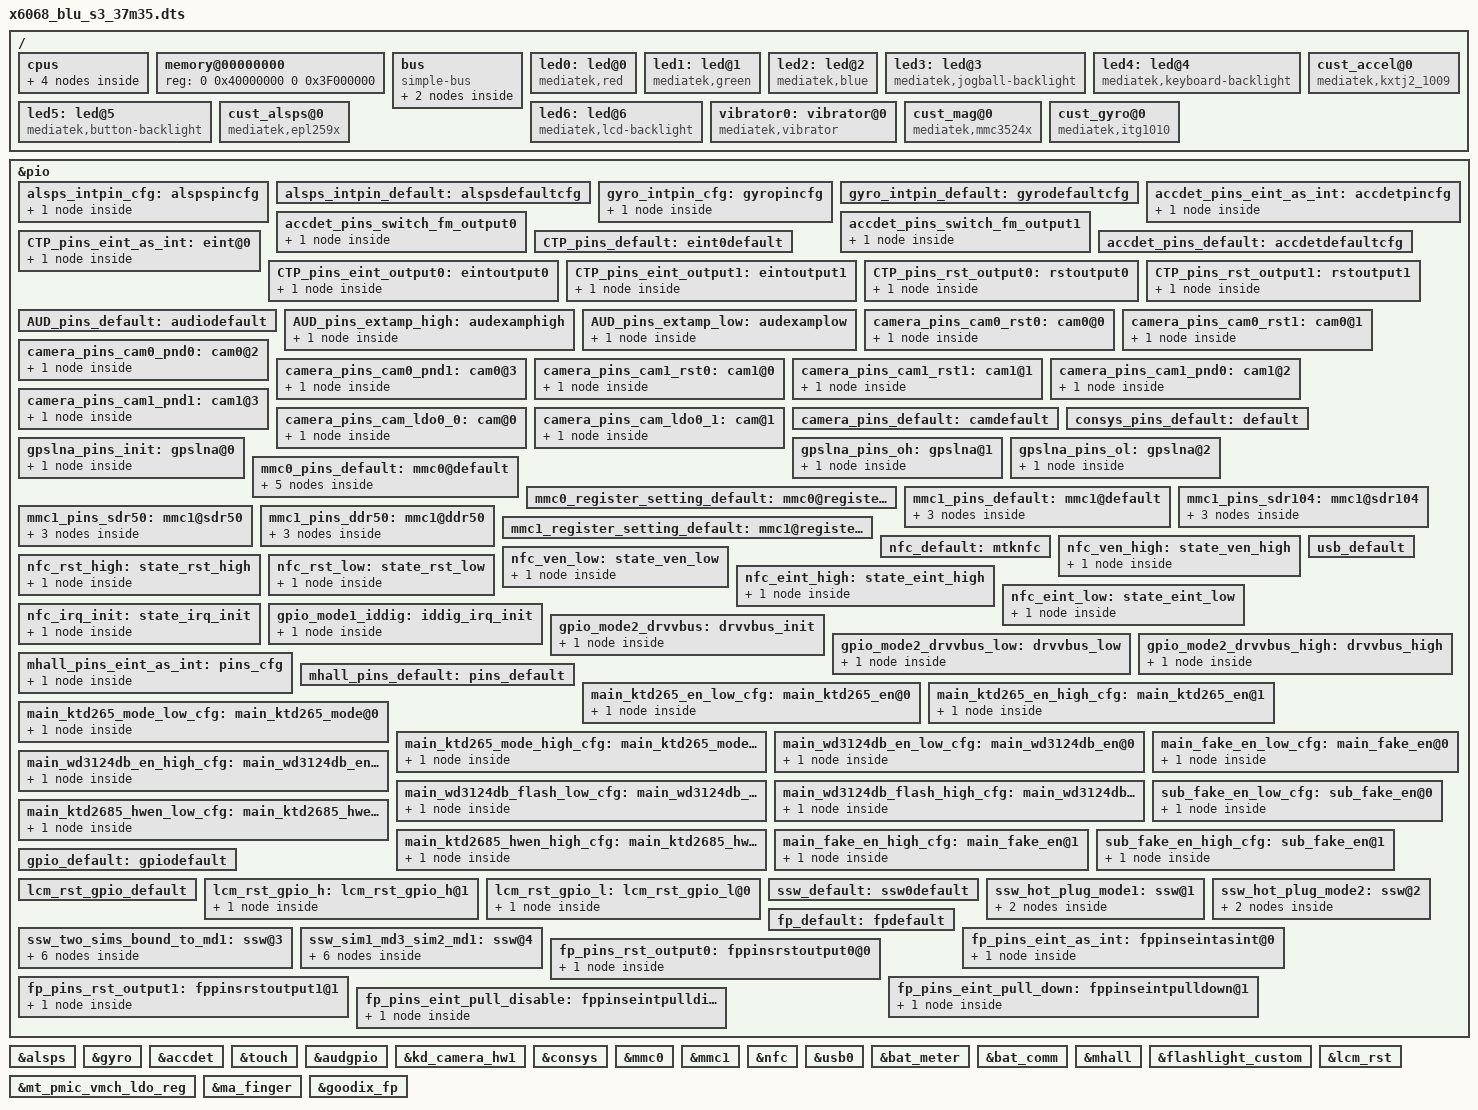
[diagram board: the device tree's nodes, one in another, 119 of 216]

/dts-v1/;

#include "mt6735m.dtsi"

/ {
	cpus {
		#address-cells = <1>;
		#size-cells = <0>;
/*		enable-method = "mediatek,mt6735-smp"; */

		cpu0: cpu@000 {
			device_type = "cpu";
			compatible = "arm,cortex-a53";
			reg = <0x000>;
			enable-method = "spin-table";
			cpu-release-addr = <0x0 0x40000200>;
			clock-frequency = <1100000000>;
		};

		cpu1: cpu@001 {
			device_type = "cpu";
			compatible = "arm,cortex-a53";
			reg = <0x001>;
			enable-method = "spin-table";
			cpu-release-addr = <0x0 0x40000200>;
			clock-frequency = <1100000000>;
		};

		cpu2: cpu@002 {
			device_type = "cpu";
			compatible = "arm,cortex-a53";
			reg = <0x002>;
			enable-method = "spin-table";
			cpu-release-addr = <0x0 0x40000200>;
			clock-frequency = <1100000000>;
		};

		cpu3: cpu@003 {
			device_type = "cpu";
			compatible = "arm,cortex-a53";
			reg = <0x003>;
			enable-method = "spin-table";
			cpu-release-addr = <0x0 0x40000200>;
			clock-frequency = <1100000000>;
		};
	};

	memory@00000000 {
		device_type = "memory";
		reg = <0 0x40000000 0 0x3F000000>;
	};

	bus {
		compatible = "simple-bus";
		#address-cells = <1>;
		#size-cells = <1>;
		ranges = <0 0 0 0xffffffff>;

		MALI@0x13040000 {
			compatible = "arm,malit720", "arm,mali-t72x", "arm,malit7xx", "arm,mali-midgard";
			reg = <0x13040000 0x4000>;
			interrupts = <0 212 0x8>, <0 211 0x8>, <0 210 0x8>;
			interrupt-names = "JOB", "MMU", "GPU";
			clock-frequency = <550000000>;
		};

		MTKFB@5e200000 {
			compatible = "mediatek,MTKFB";
			reg = <0x7F000000 0x1000000>;
		};

	};
	led0:led@0 {
		compatible = "mediatek,red";
		led_mode = <3>;
		data = <1>;
		pwm_config = <0 0 0 0 0>;
	};
	led1:led@1 {
		compatible = "mediatek,green";
		led_mode = <3>;
		data = <1>;
		pwm_config = <0 0 0 0 0>;
	};
	led2:led@2 {
		compatible = "mediatek,blue";
		led_mode = <3>;
		data = <1>;
		pwm_config = <0 0 0 0 0>;
	};
	led3:led@3 {
		compatible = "mediatek,jogball-backlight";
		led_mode = <0>;
		data = <1>;
		pwm_config = <0 0 0 0 0>;
	};
	led4:led@4 {
		compatible = "mediatek,keyboard-backlight";
		led_mode = <0>;
		data = <1>;
		pwm_config = <0 0 0 0 0>;
	};
	led5:led@5 {
		compatible = "mediatek,button-backlight";
		led_mode = <0>;
		data = <1>;
		pwm_config = <0 0 0 0 0>;
	};
	led6:led@6 {
		compatible = "mediatek,lcd-backlight";
		led_mode = <5>;
		data = <1>;
		pwm_config = <0 0 0 0 0>;
	};
	vibrator0:vibrator@0 {
		compatible = "mediatek,vibrator";
		vib_timer = <25>;
		vib_limit = <9>;
		vib_vol= <5>;
	};
 /* sensor standardization */
		cust_accel@0 {
		compatible = "mediatek,kxtj2_1009";
		i2c_num	= <2>;
		i2c_addr = <0x0E 0 0 0>;
		direction = <7>;
		power_id = <0xffff>;
		power_vol = <0>;
		firlen = <0>;
		is_batch_supported = <0>;
		};

		cust_alsps@0 {
		compatible = "mediatek,epl259x";
		i2c_num	= <2>;
		i2c_addr = <0x49 0 0 0>;
		polling_mode_ps = <0>;
		polling_mode_als = <1>;
		power_id = <0xffff>;
		power_vol = <0>;
		als_level = <20  45  70  90  150  300  500  700  1400  3600  5500  8000  15000  30000  50000>;
		als_value = <10  30  60  80  100  200  400  600  800  1000  3650  6000  10000  20000  40000  60000>;
		ps_threshold_high		=  <34>;
		ps_threshold_low		=  <28>;
		is_batch_supported_ps	= <0>;
		is_batch_supported_als	= <0>;
		ps_integration_time     =<24 >;/*epl259x use*/
		};

		cust_mag@0 {
		compatible				= "mediatek,mmc3524x";
		i2c_num					= <2>;
		i2c_addr				= <0x30 0 0 0>;
		direction				= <0>;
		power_id				= <0xffff>;
		power_vol				= <0>;
		is_batch_supported	= <0>;
		};

		cust_gyro@0 {
		compatible				= "mediatek,itg1010";
		i2c_num				= <2>;
		i2c_addr				= <0x68 0 0 0>;
		direction				= <3>;
		power_id				= <0xffff>;
		power_vol				= <0>;
		firlen					= <0>;
		is_batch_supported	= <0>;
		};
};
/* sensor gpio standization */
&pio {
	alsps_intpin_cfg: alspspincfg {

	    pins_cmd_dat {
			pins = <PINMUX_GPIO80__FUNC_GPIO80>;
			slew-rate = <0>;
			bias-pull-up = <00>;
		};
	};

	alsps_intpin_default: alspsdefaultcfg {

	};

	gyro_intpin_cfg: gyropincfg {

		pins_cmd_dat {
			pins = <PINMUX_GPIO67__FUNC_GPIO67>;
			slew-rate = <0>;
			bias-pull-down = <00>;
		};
	};

	gyro_intpin_default: gyrodefaultcfg {

	};
};
&alsps {
	pinctrl-names = "pin_default", "pin_cfg";
	pinctrl-0 = <&alsps_intpin_default>;
	pinctrl-1 = <&alsps_intpin_cfg>;
	status = "okay";

};

&gyro {
	pinctrl-names = "pin_default", "pin_cfg";
	pinctrl-0 = <&gyro_intpin_default>;
	pinctrl-1 = <&gyro_intpin_cfg>;
	status = "okay";

};
/* sensor end */

/* ACCDET start */
&pio {
	accdet_pins_eint_as_int: accdetpincfg {
	
		pins_cmd_dat {
		pins = <PINMUX_GPIO6__FUNC_GPIO6>;
		slew-rate = <0>;
		bias-disable;
		};
	};
	
	accdet_pins_switch_fm_output0: accdet_pins_switch_fm_output0 {
		pins_cmd_dat {
			pins = <PINMUX_GPIO11__FUNC_GPIO11>;
			slew-rate = <1>;
			output-low;
		};
	};
	accdet_pins_switch_fm_output1: accdet_pins_switch_fm_output1 {
		pins_cmd_dat {
			pins = <PINMUX_GPIO11__FUNC_GPIO11>;
			slew-rate = <1>;
			output-high;
		};
	};
	
	accdet_pins_default: accdetdefaultcfg {
	
	};
};
&accdet {
	accdet-mic-vol = <7>;
	switch_fm_support = <1>;  /* support*/
	headset-mode-setting = <0x500 0x200 1 0x1F0 0x800 0x800 0x20>;
	accdet-plugout-debounce = <20>;
	/*1:ACC mode, 2:low cost without in bias, 6:low cost with in bias*/
	accdet-mic-mode = <1>;
	/*0--MD_MAX--UP_MAX--DW_MAX*/
	headset-three-key-threshold = <0 80 220 500>;
	/*0--MD_MAX--VOICE_MAX--UP_MAX--DW_MAX*/
	headset-four-key-threshold = <0 58 121 192 450>;
	/* accdet+eint mode start */
	debounce = <6 256000>;
	interrupts = <6 IRQ_TYPE_LEVEL_LOW>;
	pinctrl-names = "default", "state_eint_as_int", 
						"state_switch_fm_output0", "state_switch_fm_output1";
	pinctrl-0 = <&accdet_pins_default>;
	pinctrl-1 = <&accdet_pins_eint_as_int>;
	pinctrl-2 = <&accdet_pins_switch_fm_output0>;
	pinctrl-3 = <&accdet_pins_switch_fm_output1>;
	status = "okay";
	/* accdet+eint mode end */
};
/* ACCDET end */

&touch {
	tpd-resolution = <720 1280>;
	use-tpd-button = <1>;
	tpd-key-num = <3>;
	tpd-key-local= <139 172 158 0>;
	tpd-key-dim-local = <60 1500 100 40 180 1500 100 40 300 1500 100 40 0 0 0 0>;
	tpd-max-touch-num = <5>;
	tpd-filter-enable = <0>;
	tpd-filter-pixel-density = <93>;
	tpd-filter-custom-prameters = <0 0 0 0 0 0 0 0 0 0 0 0>;
	tpd-filter-custom-speed = <0 0 0>;
	pinctrl-names = "default", "state_eint_as_int", "state_eint_output0", "state_eint_output1",
		"state_rst_output0", "state_rst_output1";
	pinctrl-0 = <&CTP_pins_default>;
	pinctrl-1 = <&CTP_pins_eint_as_int>;
	pinctrl-2 = <&CTP_pins_eint_output0>;
	pinctrl-3 = <&CTP_pins_eint_output1>;
	pinctrl-4 = <&CTP_pins_rst_output0>;
	pinctrl-5 = <&CTP_pins_rst_output1>;
	status = "okay";
};
&pio {
	CTP_pins_default: eint0default {
	};
	CTP_pins_eint_as_int: eint@0 {
		pins_cmd_dat {
			pins = <PINMUX_GPIO10__FUNC_GPIO10>;
			slew-rate = <0>;
			bias-disable;
		};
	};
	CTP_pins_eint_output0: eintoutput0 {
		pins_cmd_dat {
			pins = <PINMUX_GPIO10__FUNC_GPIO10>;
			slew-rate = <1>;
			output-low;
		};
	};
	CTP_pins_eint_output1: eintoutput1 {
		pins_cmd_dat {
			pins = <PINMUX_GPIO10__FUNC_GPIO10>;
			slew-rate = <1>;
			output-high;
		};
	};
	CTP_pins_rst_output0: rstoutput0 {
		pins_cmd_dat {
			pins = <PINMUX_GPIO62__FUNC_GPIO62>;
			slew-rate = <1>;
			output-low;
		};
	};
	CTP_pins_rst_output1: rstoutput1 {
		pins_cmd_dat {
			pins = <PINMUX_GPIO62__FUNC_GPIO62>;
			slew-rate = <1>;
			output-high;
		};
	};
};
/* TOUCH end */

&audgpio {
	aud_pa_mode_select = <1>; /*mode0~3 (1.2W,1W,0.8W,0.6W)*/
	pinctrl-names = "default", "extamp-pullhigh", "extamp-pulllow";
	pinctrl-0 = <&AUD_pins_default>;
	pinctrl-1 = <&AUD_pins_extamp_high>;
	pinctrl-2 = <&AUD_pins_extamp_low>;
	status = "okay";
};
&pio {
	AUD_pins_default: audiodefault {
	};
	AUD_pins_extamp_high: audexamphigh {
		pins_cmd_dat {
			pins = <PINMUX_GPIO61__FUNC_GPIO61>;
				slew-rate = <1>;
				output-high;
		};
	};
	AUD_pins_extamp_low: audexamplow {
		pins_cmd_dat {
			pins = <PINMUX_GPIO61__FUNC_GPIO61>;
				slew-rate = <1>;
				output-low;
		};
	};
};
/* AUDIO end */
/* CAMERA GPIO standardization */
&pio {
	camera_pins_cam0_rst0: cam0@0 {
		pins_cmd_dat {
			pins = <PINMUX_GPIO44__FUNC_GPIO44>;/*GPIO_CAMERA_CMRST_PIN*/
			slew-rate = <1>; /*direction 0:in, 1:out*/
			output-low;/*direction out used only. output_low or high*/
		};
	};
	camera_pins_cam0_rst1: cam0@1 {
	    pins_cmd_dat {
			pins = <PINMUX_GPIO44__FUNC_GPIO44>;/*GPIO_CAMERA_CMRST_PIN*/
			slew-rate = <1>;
			output-high;
		};
	};
	camera_pins_cam0_pnd0: cam0@2 {
	    pins_cmd_dat {
			pins = <PINMUX_GPIO4__FUNC_GPIO4>;/*GPIO_CAMERA_CMPDN_PIN*/
			slew-rate = <1>;
			output-low;
		};
	};
	camera_pins_cam0_pnd1: cam0@3 {
	    pins_cmd_dat {
			pins = <PINMUX_GPIO4__FUNC_GPIO4>;/*GPIO_CAMERA_CMPDN_PIN*/
			slew-rate = <1>;
			output-high;
		};
	};
	camera_pins_cam1_rst0: cam1@0 {
	    pins_cmd_dat {
			pins = <PINMUX_GPIO63__FUNC_GPIO63>;/*GPIO_CAMERA_CMRST1_PIN*/
			slew-rate = <1>; /*direction 0:in, 1:out*/
			output-low;/*direction out used only. output_low or high*/
		};
	};
	camera_pins_cam1_rst1: cam1@1 {
	    pins_cmd_dat {
			pins = <PINMUX_GPIO63__FUNC_GPIO63>;/*GPIO_CAMERA_CMRST1_PIN*/
			slew-rate = <1>;
			output-high;
		};
	};
	camera_pins_cam1_pnd0: cam1@2 {
	    pins_cmd_dat {
			pins = <PINMUX_GPIO59__FUNC_GPIO59>;/*GPIO_CAMERA_CMPDN1_PIN*/
			slew-rate = <1>;
			output-low;
		};
	};
	camera_pins_cam1_pnd1: cam1@3 {
	    pins_cmd_dat {
			pins = <PINMUX_GPIO59__FUNC_GPIO59>;/*GPIO_CAMERA_CMPDN1_PIN*/
			slew-rate = <1>;
			output-high;
		};
	};
	camera_pins_cam_ldo0_0: cam@0 {
	    pins_cmd_dat {
			pins = <PINMUX_GPIO68__FUNC_GPIO68>;/*GPIO_SPI_MOSI_PIN*/
			slew-rate = <1>;
			output-low;
		};
	};
	camera_pins_cam_ldo0_1: cam@1 {
		pins_cmd_dat {
			pins = <PINMUX_GPIO68__FUNC_GPIO68>;/*GPIO_SPI_MOSI_PIN*/
			slew-rate = <1>;
			output-high;
		};
	};
	camera_pins_default: camdefault {
	};

};

&kd_camera_hw1 {
	pinctrl-names = "default", "cam0_rst0", "cam0_rst1", "cam0_pnd0", "cam0_pnd1",
			"cam1_rst0", "cam1_rst1", "cam1_pnd0", "cam1_pnd1","cam_ldo0_0", "cam_ldo0_1";
	pinctrl-0 = <&camera_pins_default>;
	pinctrl-1 = <&camera_pins_cam0_rst0>;
	pinctrl-2 = <&camera_pins_cam0_rst1>;
	pinctrl-3 = <&camera_pins_cam0_pnd0>;
	pinctrl-4 = <&camera_pins_cam0_pnd1>;
	pinctrl-5 = <&camera_pins_cam1_rst0>;
	pinctrl-6 = <&camera_pins_cam1_rst1>;
	pinctrl-7 = <&camera_pins_cam1_pnd0>;
	pinctrl-8 = <&camera_pins_cam1_pnd1>;
	pinctrl-9 = <&camera_pins_cam_ldo0_0>;
	pinctrl-10 = <&camera_pins_cam_ldo0_1>;
	status = "okay";

};
/* CAMERA GPIO end */

/* CONSYS GPIO standardization */
&pio {
	consys_pins_default: default {

	};

	gpslna_pins_init: gpslna@0 {

		pins_cmd_dat {
			pins = <PINMUX_GPIO79__FUNC_GPIO79>;
			slew-rate = <0>;
			bias-disable;
			output-low;
		};
	};

	gpslna_pins_oh: gpslna@1 {

		pins_cmd_dat {
			pins = <PINMUX_GPIO79__FUNC_GPIO79>;
			slew-rate = <1>;
			output-high;
		};
	};

	gpslna_pins_ol: gpslna@2 {

		pins_cmd_dat {
			pins = <PINMUX_GPIO79__FUNC_GPIO79>;
			slew-rate = <1>;
			output-low;
		};
	};

};

&consys {
	pinctrl-names = "default", "gps_lna_state_init", "gps_lna_state_oh", "gps_lna_state_ol";
	pinctrl-0 = <&consys_pins_default>;
	pinctrl-1 = <&gpslna_pins_init>;
	pinctrl-2 = <&gpslna_pins_oh>;
	pinctrl-3 = <&gpslna_pins_ol>;
	status = "okay";

};
/* CONSYS end */

/* mmc start */
&mmc0 {
		clk_src = /bits/ 8 <MSDC50_CLKSRC_400MHZ>;
		bus-width = <8>;
		max-frequency = <200000000>;
		cap-mmc-highspeed;
		msdc-sys-suspend;
		mmc-ddr-1_8v;
		mmc-hs200-1_8v;
		mmc-hs400-1_8v;
		non-removable;
		pinctl = <&mmc0_pins_default>;
		register_setting = <&mmc0_register_setting_default>;
		host_function = /bits/ 8 <MSDC_EMMC>;
		bootable;
		status = "okay";
};

&mmc1 {
		clk_src = /bits/ 8 <MSDC30_CLKSRC_200MHZ>;
		bus-width = <4>;
		max-frequency = <200000000>;
		msdc-sys-suspend;
		cap-sd-highspeed;
		sd-uhs-sdr12;
		sd-uhs-sdr25;
		sd-uhs-sdr50;
		sd-uhs-sdr104;
		sd-uhs-ddr50;
		pinctl = <&mmc1_pins_default>;
		pinctl_sdr104 = <&mmc1_pins_sdr104>;
		pinctl_sdr50 = <&mmc1_pins_sdr50>;
		pinctl_ddr50 = <&mmc1_pins_ddr50>;
		register_setting = <&mmc1_register_setting_default>;
		host_function = /bits/ 8 <MSDC_SD>;
		cd_level = /bits/ 8 <MSDC_CD_HIGH>;
		cd-gpios = <&pio 60 0>;
		sd_need_power;		
		status = "okay";
};

&pio {
	mmc0_pins_default: mmc0@default {
			pins_cmd {
				drive-strength = /bits/ 8 <2>;
			};
			pins_dat {
				drive-strength = /bits/ 8 <2>;
			};
			pins_clk {
				drive-strength = /bits/ 8 <2>;
			};
			pins_rst {
				drive-strength = /bits/ 8 <2>;
			};
			pins_ds {
				drive-strength = /bits/ 8 <2>;
			};
	};

	mmc0_register_setting_default: mmc0@register_default {
		dat0rddly	  = /bits/ 8 <0>;
		dat1rddly	  = /bits/ 8 <0>;
		dat2rddly	  = /bits/ 8 <0>;
		dat3rddly	  = /bits/ 8 <0>;
		dat4rddly	  = /bits/ 8 <0>;
		dat5rddly	  = /bits/ 8 <0>;
		dat6rddly	  = /bits/ 8 <0>;
		dat7rddly	  = /bits/ 8 <0>;
		datwrddly	  = /bits/ 8 <0>;
		cmdrrddly	  = /bits/ 8 <0>;
		cmdrddly	   = /bits/ 8 <0>;
		cmd_edge = /bits/ 8 <MSDC_SMPL_FALLING>;
		rdata_edge = /bits/ 8 <MSDC_SMPL_FALLING>;
		wdata_edge = /bits/ 8 <MSDC_SMPL_FALLING>;

		ett-hs200-cells = <12>;
		ett-hs200-default = <OFFSET_MSDC_PATCH_BIT0	MSDC_PB0_INT_DAT_LATCH_CK_SEL 0x0
			OFFSET_MSDC_PATCH_BIT0	MSDC_PB0_CKGEN_MSDC_DLY_SEL   0x0
			OFFSET_MSDC_PATCH_BIT1	MSDC_PB1_CMD_RSP_TA_CNTR	  0x1
			OFFSET_MSDC_IOCON		MSDC_IOCON_RSPL			   0x0
			OFFSET_MSDC_PAD_TUNE0	MSDC_PAD_TUNE0_CMDRDLY		0x7
			OFFSET_MSDC_PAD_TUNE0	MSDC_PAD_TUNE0_CMDRRDLY	   0xb
			OFFSET_MSDC_PATCH_BIT1		MSDC_PB1_WRDAT_CRCS_TA_CNTR   0x1
			OFFSET_MSDC_PAD_TUNE0	MSDC_PAD_TUNE0_DATWRDLY	   0xb
			OFFSET_MSDC_IOCON			MSDC_IOCON_W_D0SPL			0x0
			OFFSET_MSDC_DAT_RDDLY0		MSDC_DAT_RDDLY0_D0			0x7
			OFFSET_MSDC_PAD_TUNE0	MSDC_PAD_TUNE0_DATRRDLY	   0x9
			OFFSET_MSDC_IOCON		MSDC_IOCON_R_D_SMPL		   0x0>;

		ett-hs400-cells = <8>;
		ett-hs400-default = <OFFSET_MSDC_PATCH_BIT0	MSDC_PB0_INT_DAT_LATCH_CK_SEL	0x0
			OFFSET_MSDC_PATCH_BIT0		MSDC_PB0_CKGEN_MSDC_DLY_SEL		0x0
			OFFSET_EMMC50_PAD_DS_TUNE	MSDC_EMMC50_PAD_DS_TUNE_DLY1	0x2
			OFFSET_EMMC50_PAD_DS_TUNE	MSDC_EMMC50_PAD_DS_TUNE_DLY3	0x10
			OFFSET_MSDC_PATCH_BIT1			MSDC_PB1_CMD_RSP_TA_CNTR	0x1
			OFFSET_MSDC_IOCON		MSDC_IOCON_RSPL				0x0
			OFFSET_MSDC_PAD_TUNE0			MSDC_PAD_TUNE0_CMDRDLY		0x6
			OFFSET_MSDC_PAD_TUNE0		MSDC_PAD_TUNE0_CMDRRDLY		0x6>;
	};

	mmc1_pins_default: mmc1@default {
			pins_cmd {
				drive-strength = /bits/ 8 <3>;
			};
			pins_dat {
				drive-strength = /bits/ 8 <3>;
			};
			pins_clk {
				drive-strength = /bits/ 8 <3>;
			};
	};

	mmc1_pins_sdr104: mmc1@sdr104 {
			pins_cmd {
				drive-strength = /bits/ 8 <2>;
			};
			pins_dat {
				drive-strength = /bits/ 8 <2>;
			};
			pins_clk {
				drive-strength = /bits/ 8 <3>;
			};
	};

	mmc1_pins_sdr50: mmc1@sdr50 {
			pins_cmd {
				drive-strength = /bits/ 8 <2>;
			};
			pins_dat {
				drive-strength = /bits/ 8 <2>;
			};
			pins_clk {
				drive-strength = /bits/ 8 <3>;
			};
	};

	mmc1_pins_ddr50: mmc1@ddr50 {
			pins_cmd {
				drive-strength = /bits/ 8 <2>;
			};
			pins_dat {
				drive-strength = /bits/ 8 <2>;
			};
			pins_clk {
				drive-strength = /bits/ 8 <3>;
			};
	};

	mmc1_register_setting_default: mmc1@register_default {
				dat0rddly	  = /bits/ 8 <0>;
				dat1rddly	  = /bits/ 8 <0>;
				dat2rddly	  = /bits/ 8 <0>;
				dat3rddly	  = /bits/ 8 <0>;
				datwrddly	  = /bits/ 8 <0>;
				cmdrrddly	  = /bits/ 8 <0>;
				cmdrddly	   = /bits/ 8 <0>;
				cmd_edge = /bits/ 8 <MSDC_SMPL_FALLING>;
				rdata_edge = /bits/ 8 <MSDC_SMPL_FALLING>;
				wdata_edge = /bits/ 8 <MSDC_SMPL_FALLING>;
	};
};
/* mmc end */

/* NFC GPIO standardization */
&pio {
	nfc_default: mtknfc {

	};

	nfc_ven_high: state_ven_high {
		pins_cmd_dat {
			pins = <PINMUX_GPIO4__FUNC_GPIO4>;
			slew-rate = <1>;
			output-high;
		};
	};

	nfc_ven_low: state_ven_low {
		pins_cmd_dat {
			pins = <PINMUX_GPIO4__FUNC_GPIO4>;
			slew-rate = <1>;
			output-low;
		};
	};

	nfc_rst_high: state_rst_high {
		pins_cmd_dat {
			pins = <PINMUX_GPIO3__FUNC_GPIO3>;
			slew-rate = <1>;
			output-high;
		};
	};

	nfc_rst_low: state_rst_low {
		pins_cmd_dat {
			pins = <PINMUX_GPIO3__FUNC_GPIO3>;
			slew-rate = <1>;
			output-low;
		};
	};

	nfc_eint_high: state_eint_high {
		pins_cmd_dat {
			pins = <PINMUX_GPIO1__FUNC_GPIO1>;
			slew-rate = <1>;
			output-high;
		};
	};

	nfc_eint_low: state_eint_low {
		pins_cmd_dat {
			pins = <PINMUX_GPIO1__FUNC_GPIO1>;
			slew-rate = <1>;
			output-low;
		};
	};

	nfc_irq_init: state_irq_init {
		pins_cmd_dat {
			pins = <PINMUX_GPIO2__FUNC_GPIO2>;
			slew-rate = <0>;
			bias-pull-down = <00>;
		};
	};
};

&nfc {
	pinctrl-names = "mtknfc", "ven_high", "ven_low", "rst_high", "rst_low", "eint_high", "eint_low", "irq_init";
	pinctrl-0 = <&nfc_default>;
	pinctrl-1 = <&nfc_ven_high>;
	pinctrl-2 = <&nfc_ven_low>;
	pinctrl-3 = <&nfc_rst_high>;
	pinctrl-4 = <&nfc_rst_low>;
	pinctrl-5 = <&nfc_eint_high>;
	pinctrl-6 = <&nfc_eint_low>;
	pinctrl-7 = <&nfc_irq_init>;
	status = "okay";
};
/* NFC end */

/* USB GPIO Kernal Standardization start */
&pio {
	usb_default: usb_default {
	};

	gpio_mode1_iddig: iddig_irq_init {
		pins_cmd_dat {
			pins = <PINMUX_GPIO0__FUNC_GPIO0>;
			slew-rate = <0>;
			bias-pull-up = <00>;
		};
	};

	gpio_mode2_drvvbus: drvvbus_init {
		pins_cmd_dat {
			pins = <PINMUX_GPIO82__FUNC_GPIO82>;
			slew-rate = <1>;
			bias-pull-down = <00>;
		};
	};

	gpio_mode2_drvvbus_low: drvvbus_low {
		pins_cmd_dat {
			pins = <PINMUX_GPIO82__FUNC_GPIO82>;
			slew-rate = <1>;
			output-low;
			bias-pull-down = <00>;
		};
	};

	gpio_mode2_drvvbus_high: drvvbus_high {
		pins_cmd_dat {
			pins = <PINMUX_GPIO82__FUNC_GPIO82>;
			slew-rate = <1>;
			output-high;
			bias-pull-down = <00>;
		};
	};
};

&usb0 {
	iddig_gpio = <0 1>;
	drvvbus_gpio = <82 2>;
	pinctrl-names = "usb_default", "iddig_irq_init", "drvvbus_init", "drvvbus_low", "drvvbus_high";
	pinctrl-0 = <&usb_default>;
	pinctrl-1 = <&gpio_mode1_iddig>;
	pinctrl-2 = <&gpio_mode2_drvvbus>;
	pinctrl-3 = <&gpio_mode2_drvvbus_low>;
	pinctrl-4 = <&gpio_mode2_drvvbus_high>;
	status = "okay";
};
/* USB GPIO Kernal Standardization end */
/*charger start*/
&bat_meter {
			/* cust_battery_meter.h */
			/* ADC resistor  */
			r_bat_sense = <4 >;
			r_i_sense = <4 >;
			r_charger_1 = <330 >;
			r_charger_2 = <39 >;
			temperature_t0 = <110 >;
			temperature_t1 = <0 >;
			temperature_t2 = <25 >;
			temperature_t3 = <50 >;
			temperature_t = <255 >;	/* this should be fixed, never change the value */
			fg_meter_resistance = <0 >;

			/* Qmax for 0mA */
			q_max_pos_50 = <3808 >;
			q_max_pos_25 = <3814 >;
			q_max_pos_0  = <3777 >;
			q_max_neg_10 = <3767 >;
			/* Qmax for 400mA, said high current */
			q_max_pos_50_h_current = <3800 >;
			q_max_pos_25_h_current = <3802 >;
			q_max_pos_0_h_current  = <3595 >;
			q_max_neg_10_h_current = <2552 >;
			/* Discharge percentage, 1: D5, 0: D2 */
			oam_d5 = <0 >;

			change_tracking_point = <1 >;
			/* SW OCV tracking setting */
			cust_tracking_point = <1 >;
			cust_r_sense = <33 >;
			cust_hw_cc = <0 >;
			aging_tuning_value = <103 >;
			cust_r_fg_offset = <0 >;
			ocv_board_compesate = <0 >;
			r_fg_board_base = <1000 >;
			r_fg_board_slope = <1000 >;
			car_tune_value = <100 >;

			/* HW Fuel gague  */
			current_detect_r_fg = <10 >;	/* Unit: mA */
			minerroroffset = <1000 >;
			fg_vbat_average_size = <18 >;
			r_fg_value = <10 >;	/* Unit: mOhm */

			cust_poweron_delta_capacity_tolrance = <30 >;
			cust_poweron_low_capacity_tolrance = <5 >;
			cust_poweron_max_vbat_tolrance = <90 >;
			cust_poweron_delta_vbat_tolrance = <30 >;
			cust_poweron_delta_hw_sw_ocv_capacity_tolrance = <10 >;

			/* Fixed battery temperature */
			fixed_tbat_25 = <0 >;
			/* Dynamic change wake up period of battery thread when suspend */
			vbat_normal_wakeup = <3600 >;	/* Unit: mV */
			vbat_low_power_wakeup = <3500 >;	/* Unit: mV */
			normal_wakeup_period = <5400 >;	/* Unit: second */
			low_power_wakeup_period = <300 >;	/* Unit: second */
			close_poweroff_wakeup_period = <30 >;	/* Unit: second */

			rbat_pull_up_r = <16900 >;
			rbat_pull_up_volt = <1800 >;


			batt_temperature_table_num = <17 >;
			batt_temperature_table = <
			    (-20) 68237
			    (-15) 53650
			    (-10) 42506
			    (-5) 33892
			    0 24219
			    5 22021
			    10 17926
			    15 14674
			    20 12081
			    25 10000 30 8315 35 6948 40 5834 45 4917 50 4161 55 3535 60 3014 >;
			battery_profile_t0_num = <78 >;
			battery_profile_t0 = <
				0    4326
				1    4301
				2    4280
				3    4261
				5    4242
				6    4225
				7    4209
				9    4193
				10   4178
				11   4162
				13   4147
				14   4132
				15   4117
				17   4104
				18   4094
				19   4082
				21   4066
				22   4045
				23   4021
				25   3998
				26   3980
				27   3966
				29   3953
				30   3943
				31   3935
				33   3927
				34   3918
				35   3909
				37   3899
				38   3890
				39   3881
				41   3872
				42   3864
				43   3856
				45   3849
				46   3842
				47   3835
				49   3829
				50   3822
				51   3817
				53   3812
				54   3807
				55   3802
				57   3798
				58   3796
				59   3793
				61   3791
				62   3789
				63   3786
				65   3784
				66   3781
				67   3779
				69   3776
				70   3774
				71   3771
				72   3767
				74   3764
				75   3759
				76   3755
				78   3750
				79   3745
				80   3740
				82   3734
				83   3727
				84   3721
				86   3712
				87   3708
				88   3703
				90   3697
				91   3693
				92   3684
				94   3673
				95   3655
				96   3621
				98   3564
				99   3469
				100  3400
				100  3400>;
			battery_profile_t1_num = <78 >;
			battery_profile_t1 = <
				 0    4319
				 1    4295
				 2    4276
				 3    4259
				 5    4243
				 6    4227
				 7    4211
				 9    4197
				 10   4183
				 11   4169
				 13   4156
				 14   4142
				 15   4128
				 17   4115
				 18   4103
				 19   4093
				 21   4084
				 22   4074
				 23   4058
				 25   4035
				 26   4013
				 27   3995
				 29   3982
				 30   3971
				 31   3963
				 33   3956
				 34   3948
				 35   3938
				 37   3928
				 38   3917
				 39   3906
				 41   3895
				 42   3885
				 43   3875
				 45   3867
				 46   3859
				 47   3851
				 49   3844
				 50   3838
				 51   3831
				 52   3825
				 54   3820
				 55   3816
				 56   3811
				 58   3807
				 59   3803
				 60   3799
				 62   3795
				 63   3792
				 64   3789
				 66   3787
				 67   3785
				 68   3784
				 70   3782
				 71   3780
				 72   3778
				 74   3776
				 75   3773
				 76   3769
				 78   3765
				 79   3761
				 80   3756
				 82   3750
				 83   3743
				 84   3736
				 86   3725
				 87   3718
				 88   3706
				 90   3704
				 91   3699
				 92   3695
				 94   3688
				 95   3677
				 96   3648
				 98   3584
				 99   3485
				 100  3400
				 100  3400>;
			battery_profile_t2_num = <78 >;
			battery_profile_t2 = <
				0    4312
				1    4295
				2    4279
				3    4264
				5    4249
				6    4234
				7    4219
				9    4204
				10   4190
				11   4176
				13   4162
				14   4148
				15   4135
				17   4121
				18   4107
				19   4094
				20   4081
				22   4070
				23   4063
				24   4050
				26   4031
				27   4013
				28   3999
				30   3990
				31   3983
				32   3976
				34   3967
				35   3957
				36   3947
				38   3937
				39   3927
				40   3916
				41   3903
				43   3888
				44   3875
				45   3864
				47   3855
				48   3847
				49   3840
				51   3834
				52   3828
				53   3823
				55   3818
				56   3813
				57   3808
				58   3804
				60   3800
				61   3796
				62   3793
				64   3789
				65   3786
				66   3783
				68   3780
				69   3777
				70   3774
				72   3770
				73   3766
				74   3762
				76   3758
				77   3753
				78   3748
				79   3744
				81   3739
				82   3734
				83   3727
				85   3719
				86   3712
				87   3702
				89   3692
				90   3690
				91   3688
				93   3687
				94   3684
				95   3676
				97   3634
				98   3564
				99   3459
				100  3400>;
			battery_profile_t3_num = <78 >;
			battery_profile_t3 = <
				0    4312
				1    4295
				2    4279
				3    4264
				5    4248
				6    4233
				7    4219
				9    4204
				10   4190
				11   4175
				13   4161
				14   4147
				15   4134
				17   4120
				18   4106
				19   4093
				21   4080
				22   4068
				23   4055
				24   4043
				26   4031
				27   4019
				28   4008
				30   3997
				31   3986
				32   3976
				34   3965
				35   3955
				36   3945
				38   3936
				39   3926
				40   3915
				42   3901
				43   3886
				44   3873
				45   3863
				47   3854
				48   3847
				49   3840
				51   3833
				52   3827
				53   3822
				55   3816
				56   3811
				57   3807
				59   3802
				60   3798
				61   3794
				63   3790
				64   3786
				65   3783
				66   3780
				68   3776
				69   3773
				70   3767
				72   3758
				73   3750
				74   3745
				76   3740
				77   3735
				78   3729
				80   3725
				81   3721
				82   3716
				84   3709
				85   3701
				86   3694
				87   3683
				89   3677
				90   3675
				91   3674
				93   3672
				94   3668
				95   3654
				97   3606
				98   3536
				99   3430
				100  3400>;
			r_profile_t0_num = <78 >;
			r_profile_t0 = <
				1057  4326
				1057  4301
				1060  4280
				1056  4261
				1046  4242
				1037  4225
				1026  4209
				1017  4193
				1010  4178
				999   4162
				990   4147
				978   4132
				967   4117
				961   4104
				963   4094
				964   4082
				957   4066
				938   4045
				909   4021
				886   3998
				872   3980
				860   3966
				856   3953
				851   3943
				851   3935
				851   3927
				850   3918
				847   3909
				843   3899
				843   3890
				814   3881
				836   3872
				834   3864
				834   3856
				835   3849
				835   3842
				838   3835
				839   3829
				843   3822
				844   3817
				848   3812
				850   3807
				853   3802
				857   3798
				864   3796
				871   3793
				880   3791
				889   3789
				901   3786
				915   3784
				929   3781
				948   3779
				968   3776
				994   3774
				1019  3771
				1049  3767
				1084  3764
				1119  3759
				1163  3755
				1210  3750
				1262  3745
				1318  3740
				1377  3734
				1436  3727
				1496  3721
				1541  3712
				1551  3708
				1640  3703
				1671  3697
				1704  3693
				1734  3684
				1778  3673
				1825  3655
				1881  3621
				1960  3564
				2094  3469
				2094  3400
				2094  3400>;
			r_profile_t1_num = <78 >;
			r_profile_t1 = <
				356   4319
				356   4295
				356   4276
				357   4259
				358   4243
				356   4227
				355   4211
				354   4197
				353   4183
				352   4169
				351   4156
				351   4142
				350   4128
				350   4115
				347   4103
				350   4093
				363   4084
				374   4074
				371   4058
				358   4035
				346   4013
				338   3995
				335   3982
				333   3971
				332   3963
				333   3956
				330   3948
				325   3938
				319   3928
				313   3917
				308   3906
				301   3895
				298   3885
				294   3875
				291   3867
				289   3859
				284   3851
				286   3844
				285   3838
				285   3831
				284   3825
				289   3820
				286   3816
				288   3811
				289   3807
				290   3803
				291   3799
				292   3795
				292   3792
				295   3789
				295   3787
				297   3785
				299   3784
				303   3782
				305   3780
				311   3778
				316   3776
				321   3773
				326   3769
				334   3765
				343   3761
				351   3756
				364   3750
				374   3743
				388   3736
				398   3725
				399   3718
				436   3706
				448   3704
				510   3699
				564   3695
				630   3688
				714   3677
				805   3648
				922   3584
				1130  3485
				1130  3400
				1130  3400>;
			r_profile_t2_num = <78 >;
			r_profile_t2 = <
				92   4312
				92   4295
				90   4279
				91   4264
				92   4249
				95   4234
				95   4219
				95   4204
				96   4190
				98   4176
				98   4162
				99   4148
				102  4135
				109  4121
				107  4107
				104  4094
				105  4081
				107  4070
				111  4063
				115  4050
				115  4031
				117  4013
				120  3999
				123  3990
				124  3983
				126  3976
				123  3967
				116  3957
				105  3947
				94   3937
				90   3927
				86   3916
				85   3903
				83   3888
				84   3875
				84   3864
				83   3855
				83   3847
				83   3840
				84   3834
				85   3828
				84   3823
				86   3818
				88   3813
				89   3808
				90   3804
				91   3800
				92   3796
				91   3793
				90   3789
				89   3786
				87   3783
				84   3780
				83   3777
				82   3774
				82   3770
				82   3766
				81   3762
				82   3758
				82   3753
				82   3748
				82   3744
				81   3739
				82   3734
				83   3727
				82   3719
				84   3712
				85   3702
				81   3692
				82   3690
				85   3688
				91   3687
				98   3684
				108  3676
				98   3634
				107  3564
				125  3459
				125  3400>;
			r_profile_t3_num = <78 >;
			r_profile_t3 = <
				53  4312
				53  4295
				54  4279
				53  4264
				54  4248
				53  4233
				53  4219
				54  4204
				55  4190
				55  4175
				56  4161
				56  4147
				57  4134
				56  4120
				57  4106
				58  4093
				59  4080
				60  4068
				60  4055
				62  4043
				62  4031
				62  4019
				64  4008
				65  3997
				67  3986
				68  3976
				70  3965
				72  3955
				74  3945
				77  3936
				79  3926
				80  3915
				75  3901
				65  3886
				58  3873
				56  3863
				55  3854
				54  3847
				56  3840
				54  3833
				54  3827
				56  3822
				56  3816
				56  3811
				57  3807
				58  3802
				59  3798
				60  3794
				62  3790
				64  3786
				64  3783
				66  3780
				66  3776
				68  3773
				65  3767
				56  3758
				55  3750
				56  3745
				56  3740
				56  3735
				55  3729
				56  3725
				57  3721
				58  3716
				56  3709
				55  3701
				58  3694
				56  3683
				54  3677
				55  3675
				58  3674
				63  3672
				68  3668
				68  3654
				64  3606
				72  3536
				82  3430
				82  3400>;
};

&bat_comm {
			/* cust_charging.h */
			/* stop charging while in talking mode */
			stop_charging_in_takling = <1 >;
			talking_recharge_voltage = <3800 >;
			talking_sync_time = <60 >;

			/* Battery Temperature Protection */
			mtk_temperature_recharge_support = <1 >;
			max_charge_temperature = <55 >;
			max_charge_temperature_minus_x_degree = <50 >;
			min_charge_temperature = <0 >;
			min_charge_temperature_plus_x_degree = <3 >;
			err_charge_temperature = <0xff >;

			/* Linear Charging Threshold */
			v_pre2cc_thres = <3400 >;	/* unit: mV */
			v_cc2topoff_thres = <4200 >;
			recharging_voltage = <4250 >;
			charging_full_current = <180 >;	/* unit: mA */

			/* Charging Current Setting */
			config_usb_if = <0 >;
			usb_charger_current_suspend = <0 >;	/* Unit: 0.01 mA */
			usb_charger_current_unconfigured = <7000 >;	/* Unit: 0.01 mA */
			usb_charger_current_configured = <50000 >;	/* Unit: 0.01 mA */
			usb_charger_current = <50000 >;	/* Unit: 0.01 mA */
			ac_charger_current = <150000 >;	/* Unit: 0.01 mA */
			non_std_ac_charger_current = <50000 >;	/* Unit: 0.01 mA */
			charging_host_charger_current = <65000 >;	/* Unit: 0.01 mA */
			apple_0_5a_charger_current = <50000 >;	/* Unit: 0.01 mA */
			apple_1_0a_charger_current = <65000 >;	/* Unit: 0.01 mA */
			apple_2_1a_charger_current = <80000 >;	/* Unit: 0.01 mA */

			/* charger error check */
			bat_low_temp_protect_enable = <1 >;
			v_charger_enable = <0 >;	/* 1:on , 0:off */
			v_charger_max = <6500 >;	/* unit: mV */
			v_charger_min = <4400 >;

			/*  Tracking TIME */
			onehundred_percent_tracking_time = <10 >;	/* Unit: second */
			npercent_tracking_time = <20 >;	/* Unit: second */
			sync_to_real_tracking_time = <60 >;	/* Unit: second */
			v_0percent_tracking = <3450 >;	/* Unit: mV */

			/* High battery support */
			high_battery_voltage_support = <1 >;
		};


/* charger  end */

/*mhall start*/
&pio {
	mhall_pins_eint_as_int: pins_cfg {

	    pins_cmd_dat {
			pins = <PINMUX_GPIO7__FUNC_GPIO7>;
			slew-rate = <0>;
			bias-disable;
		};
	};

	mhall_pins_default: pins_default {

	};
};

&mhall {
	pinctrl-names = "default", "state_eint_as_int";
	pinctrl-0 = <&mhall_pins_default>;
	pinctrl-1 = <&mhall_pins_eint_as_int>;
	status = "okay";
};
/*mhall end*/

/* flashlight_custom start */
&pio {
	main_ktd265_en_low_cfg: main_ktd265_en@0 {
	    pins_cmd_dat {
			pins = <PINMUX_GPIO43__FUNC_GPIO43>;
			slew-rate = <1>;
			output-low;
		};
	};
	main_ktd265_en_high_cfg: main_ktd265_en@1 {
	    pins_cmd_dat {
			pins = <PINMUX_GPIO43__FUNC_GPIO43>;
			slew-rate = <1>;
			output-high;
		};
	};
	main_ktd265_mode_low_cfg: main_ktd265_mode@0 {
	    pins_cmd_dat {
			pins = <PINMUX_GPIO42__FUNC_GPIO42>;
			slew-rate = <1>;
			output-low;
		};
	};
	main_ktd265_mode_high_cfg: main_ktd265_mode@1 {
	    pins_cmd_dat {
			pins = <PINMUX_GPIO42__FUNC_GPIO42>;
			slew-rate = <1>;
			output-high;
		};
	};
	main_wd3124db_en_low_cfg: main_wd3124db_en@0 {
	    pins_cmd_dat {
			pins = <PINMUX_GPIO42__FUNC_GPIO42>;
			slew-rate = <1>;
			output-low;
		};
	};
	main_wd3124db_en_high_cfg: main_wd3124db_en@1 {
	    pins_cmd_dat {
			pins = <PINMUX_GPIO42__FUNC_GPIO42>;
			slew-rate = <1>;
			output-high;
		};
	};
	main_wd3124db_flash_low_cfg: main_wd3124db_flash@0 {
	    pins_cmd_dat {
			pins = <PINMUX_GPIO43__FUNC_GPIO43>;
			slew-rate = <1>;
			output-low;
		};
	};
	main_wd3124db_flash_high_cfg: main_wd3124db_flash@1 {
	    pins_cmd_dat {
			pins = <PINMUX_GPIO43__FUNC_GPIO43>;
			slew-rate = <1>;
			output-high;
		};
	};
	main_ktd2685_hwen_low_cfg: main_ktd2685_hwen@0 {
	    pins_cmd_dat {
			pins = <PINMUX_GPIO42__FUNC_GPIO42>;
			slew-rate = <1>;
			output-low;
		};
	};
	main_ktd2685_hwen_high_cfg: main_ktd2685_hwen@1 {
	    pins_cmd_dat {
			pins = <PINMUX_GPIO42__FUNC_GPIO42>;
			slew-rate = <1>;
			output-high;
		};
	};
	main_fake_en_low_cfg: main_fake_en@0 {
	    pins_cmd_dat {
			pins = <PINMUX_GPIO42__FUNC_GPIO42>;
			slew-rate = <1>;
			output-low;
		};
	};
	main_fake_en_high_cfg: main_fake_en@1 {
	    pins_cmd_dat {
			pins = <PINMUX_GPIO42__FUNC_GPIO42>;
			slew-rate = <1>;
			output-high;
		};
	};
	sub_fake_en_low_cfg: sub_fake_en@0 {
	    pins_cmd_dat {
			pins = <PINMUX_GPIO57__FUNC_GPIO57>;
			slew-rate = <1>;
			output-low;
		};
	};
	sub_fake_en_high_cfg: sub_fake_en@1 {
	    pins_cmd_dat {
			pins = <PINMUX_GPIO57__FUNC_GPIO57>;
			slew-rate = <1>;
			output-high;
		};
	};
	gpio_default: gpiodefault {
	};

};

&flashlight_custom {
	flashlight_main_support = <1 1>; /*1st: enable/disable  2nd: mode (gpio,ktd265,pmic,WD3124DB,ktd2685)*/
	flashlight_sub_support = <1 0>;  /*1st: enable/disable  2nd: mode (gpio,pmic)*/
	pinctrl-names = "default", 
	                "main_ktd265_en_pin_low", "main_ktd265_en_pin_high", "main_ktd265_mode_pin_low", "main_ktd265_mode_pin_high", 
	                "main_wd3124db_en_pin_low", "main_wd3124db_en_pin_high", "main_wd3124db_flash_pin_low", "main_wd3124db_flash_pin_high", 	
	                "main_ktd2685_hwen_pin_low","main_ktd2685_hwen_pin_high",                
	                "main_fake_en_pin_low", "main_fake_en_pin_high",
	                "sub_fake_en_pin_low", "sub_fake_en_pin_high";
	pinctrl-0 = <&gpio_default>;
	pinctrl-1 = <&main_ktd265_en_low_cfg>;
	pinctrl-2 = <&main_ktd265_en_high_cfg>;
	pinctrl-3 = <&main_ktd265_mode_low_cfg>;
	pinctrl-4 = <&main_ktd265_mode_high_cfg>;		
	pinctrl-5 = <&main_wd3124db_en_low_cfg>;
	pinctrl-6 = <&main_wd3124db_en_high_cfg>;
	pinctrl-7 = <&main_wd3124db_flash_low_cfg>;
	pinctrl-8 = <&main_wd3124db_flash_high_cfg>;		
	pinctrl-9 = <&main_ktd2685_hwen_low_cfg>;
	pinctrl-10 = <&main_ktd2685_hwen_high_cfg>;	
	pinctrl-11 = <&main_fake_en_low_cfg>;
	pinctrl-12 = <&main_fake_en_high_cfg>;
	pinctrl-13 = <&sub_fake_en_low_cfg>;
	pinctrl-14 = <&sub_fake_en_high_cfg>;
	status = "okay";
};
/* flashlight_custom end */

&pio {
	lcm_rst_gpio_default: lcm_rst_gpio_default {
	};

	lcm_rst_gpio_h: lcm_rst_gpio_h@1 {
		pins_cmd_dat {
			pins = <PINMUX_GPIO146__FUNC_GPIO146>;
			slew-rate = <1>;
			output-high;
		};
	};

	lcm_rst_gpio_l: lcm_rst_gpio_l@0 {
		pins_cmd_dat {
			pins = <PINMUX_GPIO146__FUNC_GPIO146>;
			slew-rate = <1>;
			output-low;
		};
	};
};

&lcm_rst {
	lcm_need_ctl_rst = <1>;
	pinctrl-names = "default", 
	                "lcm_rst_gpio_state_h", "lcm_rst_gpio_state_l";
	pinctrl-0 = <&lcm_rst_gpio_default>;
	pinctrl-1 = <&lcm_rst_gpio_h>;
	pinctrl-2 = <&lcm_rst_gpio_l>;
	status = "okay";
};

&pio {
	ssw_default:ssw0default {
	};

	ssw_hot_plug_mode1:ssw@1 {

		pins_cmd0_dat {
			pins = <PINMUX_GPIO2__FUNC_MD_EINT0>;
		};

		pins_cmd1_dat {
			pins = <PINMUX_GPIO8__FUNC_MD_EINT1>;
		};
	};

	ssw_hot_plug_mode2:ssw@2 {

		pins_cmd0_dat {
			pins = <PINMUX_GPIO8__FUNC_C2K_UIM0_HOT_PLUG_IN>;
		};

		pins_cmd1_dat {
			pins = <PINMUX_GPIO9__FUNC_MD_EINT2>;
		};
	};

	ssw_two_sims_bound_to_md1:ssw@3 {
		pins_cmd0_dat {
			pins = <PINMUX_GPIO163__FUNC_MD_SIM1_SCLK>;
			slew-rate = <1>;
		};

		pins_cmd1_dat {
			pins = <PINMUX_GPIO164__FUNC_MD_SIM1_SRST>;
			slew-rate = <1>;
		};

		pins_cmd2_dat {
			pins = <PINMUX_GPIO165__FUNC_MD_SIM1_SDAT>;
			slew-rate = <0>;
			bias-pull-up = <00>;

		};

		pins_cmd3_dat {
			pins = <PINMUX_GPIO160__FUNC_MD_SIM2_SCLK>;
			slew-rate = <1>;
		};

		pins_cmd4_dat {
			pins = <PINMUX_GPIO161__FUNC_MD_SIM2_SRST>;
			slew-rate = <1>;
		};

		pins_cmd5_dat {
			pins = <PINMUX_GPIO162__FUNC_MD_SIM2_SDAT>;
			slew-rate = <0>;
			bias-pull-up = <00>;
		};
	};

	ssw_sim1_md3_sim2_md1:ssw@4 {
		pins_cmd0_dat {
			pins = <PINMUX_GPIO163__FUNC_UIM0_CLK>;
		};

		pins_cmd1_dat {
			pins = <PINMUX_GPIO164__FUNC_UIM0_RST>;
		};

		pins_cmd2_dat {
			pins = <PINMUX_GPIO165__FUNC_UIM0_IO>;
		};

		pins_cmd3_dat {
			pins = <PINMUX_GPIO160__FUNC_MD_SIM2_SCLK>;
		};

		pins_cmd4_dat {
			pins = <PINMUX_GPIO161__FUNC_MD_SIM2_SRST>;
		};

		pins_cmd5_dat {
			pins = <PINMUX_GPIO162__FUNC_MD_SIM2_SDAT>;
		};
	};
};
/*SSW end*/

/* lisong 2016-1-12 [BUGID:NULL][mtk patch : sim and sdcard damaged by hotplug]start */
&mt_pmic_vmch_ldo_reg {
	regulator-name = "vmch";
	regulator-boot-on;
};
/* lisong 2016-1-12 [BUGID:NULL][mtk patch : sim and sdcard damaged by hotplug]end */

&ma_finger {
	pinctrl-names = "fp_default", 
	                "fp_state_eint_as_int", "fp_state_rst_output0", "fp_state_rst_output1";
	pinctrl-0 = <&fp_default>;
	pinctrl-1 = <&fp_pins_eint_as_int>;
	pinctrl-2 = <&fp_pins_rst_output0>;
	pinctrl-3 = <&fp_pins_rst_output1>;
	status = "okay";
};

&pio {
	fp_default: fpdefault {
	};
	
	fp_pins_eint_as_int: fppinseintasint@0 {
	    pins_cmd_dat {
			pins = <PINMUX_GPIO64__FUNC_GPIO64>;
			slew-rate = <0>;
			bias-disable;
		};
	};
	
	fp_pins_rst_output0: fppinsrstoutput0@0 {
	    pins_cmd_dat {
			pins = <PINMUX_GPIO1__FUNC_GPIO1>;
			slew-rate = <1>;
			output-low;
		};
	};
	fp_pins_rst_output1: fppinsrstoutput1@1 {
	    pins_cmd_dat {
			pins = <PINMUX_GPIO1__FUNC_GPIO1>;
			slew-rate = <1>;
			output-high;
		};
	};
};


&goodix_fp {
	pinctrl-names = "fp_default", 
	                "fp_state_eint_as_int", "fp_state_eint_pull_down", "fp_state_eint_pull_disable",
	                "fp_state_rst_output0", "fp_state_rst_output1";
	pinctrl-0 = <&fp_default>;
	pinctrl-1 = <&fp_pins_eint_as_int>;
	pinctrl-2 = <&fp_pins_eint_pull_down>;		
	pinctrl-3 = <&fp_pins_eint_pull_disable>;
	pinctrl-4 = <&fp_pins_rst_output0>;
	pinctrl-5 = <&fp_pins_rst_output1>;
	status = "okay";
};

&pio {
	fp_default: fpdefault {
	};
	
	fp_pins_eint_as_int: fppinseintasint@0 {
	    pins_cmd_dat {
			pins = <PINMUX_GPIO64__FUNC_GPIO64>;
			slew-rate = <0>;
			bias-disable;
		};
	};
	fp_pins_eint_pull_down: fppinseintpulldown@1 {
	    pins_cmd_dat {
			pins = <PINMUX_GPIO64__FUNC_GPIO64>;
			slew-rate = <0>;
			bias-pull-down = <00>;
		};
	};
	fp_pins_eint_pull_disable: fppinseintpulldisable@2 {
	    pins_cmd_dat {
			pins = <PINMUX_GPIO64__FUNC_GPIO64>;
			slew-rate = <0>;
			bias-disable;
		};
	};
	
	fp_pins_rst_output0: fppinsrstoutput0@0 {
	    pins_cmd_dat {
			pins = <PINMUX_GPIO1__FUNC_GPIO1>;
			slew-rate = <1>;
			output-low;
		};
	};
	fp_pins_rst_output1: fppinsrstoutput1@1 {
	    pins_cmd_dat {
			pins = <PINMUX_GPIO1__FUNC_GPIO1>;
			slew-rate = <1>;
			output-high;
		};
	};
};

